# f29h85x_hsm_aes_s_regs register map
Vendor: Texas Instruments
Peripheral module from a debugger description file (folder HSM).
Registers are 32-bit, read-write, no defined reset value unless marked. A register's access mark holds for its fields unless they carry their own. Offsets are as the file gives them; lines under a group give offsets from that group; [hi:lo] are bit positions; {n}, {i} and the like mark numbered series; 'fields as' and 'values as' point back to an identical list; <NAME> marks a mode.

## HSM_AES_S — HSM AES S Registers
0x00 S_KEY2_6
  [31:0] KEY
0x04 S_KEY2_7
  [31:0] KEY
0x08 S_KEY2_4
  [31:0] KEY
0x0C S_KEY2_5
  [31:0] KEY
0x10 S_KEY2_2
  [31:0] KEY
0x14 S_KEY2_3
  [31:0] KEY
0x18 S_KEY2_0
  [31:0] KEY
0x1C S_KEY2_1
  [31:0] KEY
0x20 S_KEY1_6
  [31:0] KEY
0x24 S_KEY1_7
  [31:0] KEY
0x28 S_KEY1_4
  [31:0] KEY
0x2C S_KEY1_5
  [31:0] KEY
0x30 S_KEY1_2
  [31:0] KEY
0x34 S_KEY1_3
  [31:0] KEY
0x38 S_KEY1_0
  [31:0] KEY
0x3C S_KEY1_1
  [31:0] KEY
{0x40+4i} S_IV_IN_{i} (i=0..3)
  [31:0] DATA
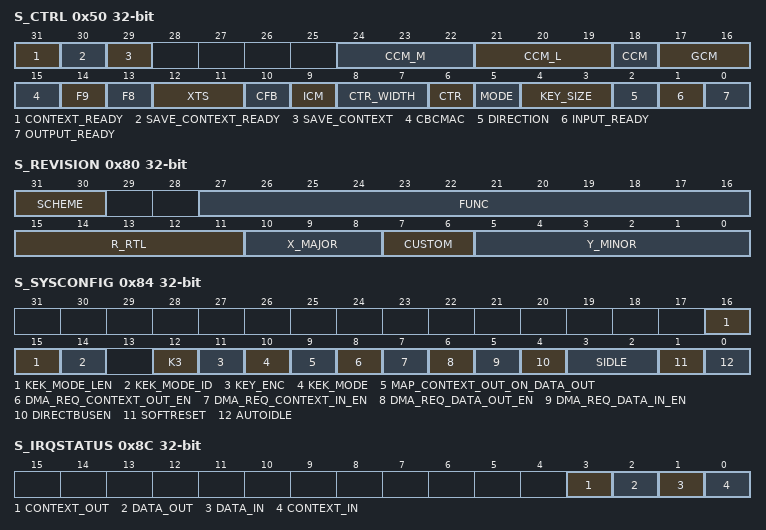
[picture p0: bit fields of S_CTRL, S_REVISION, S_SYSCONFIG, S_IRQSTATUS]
0x50 S_CTRL access per field
  [31] CONTEXT_READY ro, [30] SAVE_CONTEXT_READY ro, [29] SAVE_CONTEXT rw, [24:22] CCM_M rw, [21:19] CCM_L rw, [18] CCM rw, [17:16] GCM rw, [15] CBCMAC rw, [14] F9 rw, [13] F8 rw, [12:11] XTS rw, [10] CFB rw, [9] ICM rw, [8:7] CTR_WIDTH rw, [6] CTR rw, [5] MODE rw, [4:3] KEY_SIZE rw, [2] DIRECTION rw, [1] INPUT_READY ro, [0] OUTPUT_READY ro
0x54 S_C_LENGTH_0
  [31:0] LENGTH
0x58 S_C_LENGTH_1 access per field
  [28:0] LENGTH rw
0x5C S_AUTH_LENGTH
  [31:0] AUTH
{0x60+4i} S_DATA_IN_OUT_{i} (i=0..3)
  [31:0] DATA
{0x70+4i} S_TAG_OUT_{i} ro (i=0..3)
  [31:0] HASH
0x80 S_REVISION ro
  [31:30] SCHEME, [27:16] FUNC, [15:11] R_RTL, [10:8] X_MAJOR, [7:6] CUSTOM, [5:0] Y_MINOR
0x84 S_SYSCONFIG
  [16:15] KEK_MODE_LEN, [14] KEK_MODE_ID, [12] K3, [11] KEY_ENC, [10] KEK_MODE, [9] MAP_CONTEXT_OUT_ON_DATA_OUT, [8] DMA_REQ_CONTEXT_OUT_EN, [7] DMA_REQ_CONTEXT_IN_EN, [6] DMA_REQ_DATA_OUT_EN, [5] DMA_REQ_DATA_IN_EN, [4] DIRECTBUSEN, [3:2] SIDLE, [1] SOFTRESET, [0] AUTOIDLE
0x88 S_SYSSTATUS ro
  [0] RESETDONE
0x8C S_IRQSTATUS access per field
  [3] CONTEXT_OUT rw, [2] DATA_OUT rw, [1] DATA_IN rw, [0] CONTEXT_IN rw
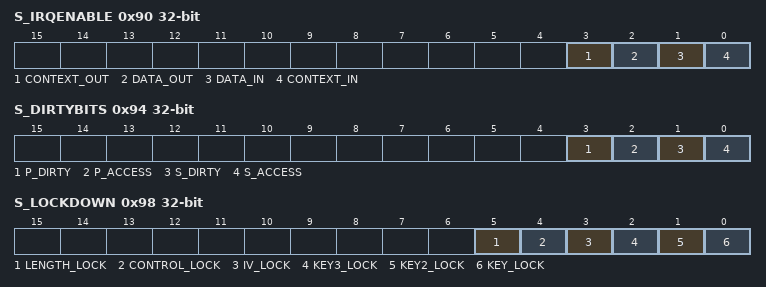
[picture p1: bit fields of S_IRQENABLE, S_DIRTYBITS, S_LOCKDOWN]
0x90 S_IRQENABLE access per field
  fields as S_IRQSTATUS
0x94 S_DIRTYBITS ro
  [3] P_DIRTY, [2] P_ACCESS, [1] S_DIRTY, [0] S_ACCESS
0x98 S_LOCKDOWN access per field
  [5] LENGTH_LOCK rw, [4] CONTROL_LOCK rw, [3] IV_LOCK rw, [2] KEY3_LOCK rw, [1] KEY2_LOCK rw, [0] KEY_LOCK rw
0xA4 S_X_CONFIG
  [0] SPEED_UP
